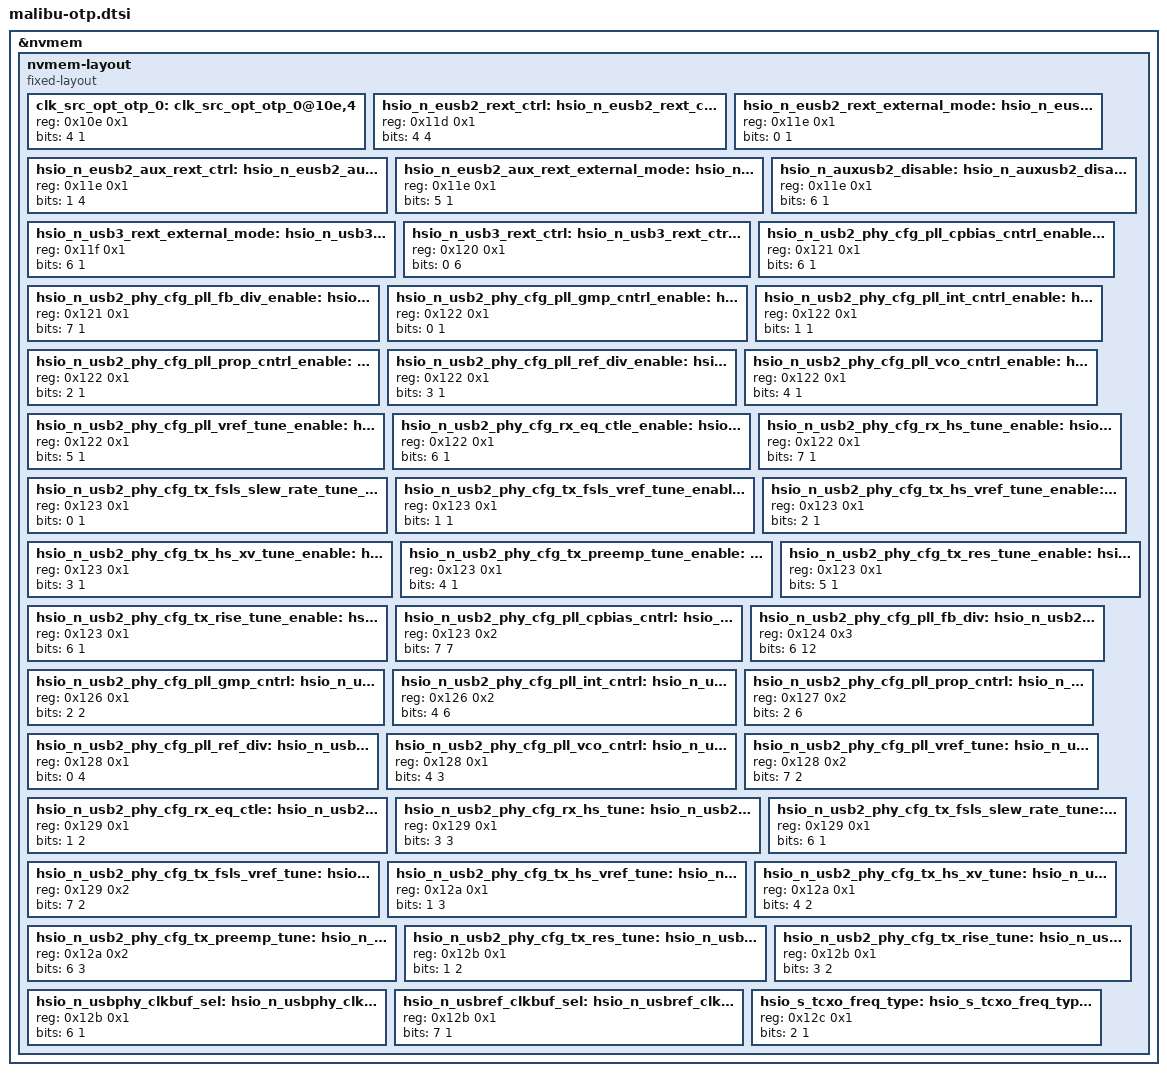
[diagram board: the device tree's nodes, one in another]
// SPDX-License-Identifier: GPL-2.0 OR BSD-3-Clause

&nvmem {
	/* OTPs */
	nvmem-layout {
		compatible = "fixed-layout";
		#address-cells = <1>;
		#size-cells = <1>;

		clk_src_opt_otp_0: clk_src_opt_otp_0@10e,4 {
			reg = <0x10e 0x1>;
			bits = <4 1>;
		};
		hsio_n_eusb2_rext_ctrl: hsio_n_eusb2_rext_ctrl@11d,4 {
			reg = <0x11d 0x1>;
			bits = <4 4>;
		};
		hsio_n_eusb2_rext_external_mode:
			hsio_n_eusb2_rext_external_mode@11e,0 {
			reg = <0x11e 0x1>;
			bits = <0 1>;
		};
		hsio_n_eusb2_aux_rext_ctrl: hsio_n_eusb2_aux_rext_ctrl@11e,1 {
			reg = <0x11e 0x1>;
			bits = <1 4>;
		};
		hsio_n_eusb2_aux_rext_external_mode:
			hsio_n_eusb2_aux_rext_external_mode@11e,5 {
			reg = <0x11e 0x1>;
			bits = <5 1>;
		};
		hsio_n_auxusb2_disable: hsio_n_auxusb2_disable@11e,6 {
			reg = <0x11e 0x1>;
			bits = <6 1>;
		};
		hsio_n_usb3_rext_external_mode:
			hsio_n_usb3_rext_external_mode@11f,6 {
			reg = <0x11f 0x1>;
			bits = <6 1>;
		};
		hsio_n_usb3_rext_ctrl: hsio_n_usb3_rext_ctrl@120,0 {
			reg = <0x120 0x1>;
			bits = <0 6>;
		};
		hsio_n_usb2_phy_cfg_pll_cpbias_cntrl_enable:
			hsio_n_usb2_phy_cfg_pll_cpbias_cntrl_enable@121,6 {
			reg = <0x121 0x1>;
			bits = <6 1>;
		};
		hsio_n_usb2_phy_cfg_pll_fb_div_enable:
			hsio_n_usb2_phy_cfg_pll_fb_div_enable@121,7 {
			reg = <0x121 0x1>;
			bits = <7 1>;
		};
		hsio_n_usb2_phy_cfg_pll_gmp_cntrl_enable:
			hsio_n_usb2_phy_cfg_pll_gmp_cntrl_enable@122,0 {
			reg = <0x122 0x1>;
			bits = <0 1>;
		};
		hsio_n_usb2_phy_cfg_pll_int_cntrl_enable:
			hsio_n_usb2_phy_cfg_pll_int_cntrl_enable@122,1 {
			reg = <0x122 0x1>;
			bits = <1 1>;
		};
		hsio_n_usb2_phy_cfg_pll_prop_cntrl_enable:
			hsio_n_usb2_phy_cfg_pll_prop_cntrl_enable@122,2 {
			reg = <0x122 0x1>;
			bits = <2 1>;
		};
		hsio_n_usb2_phy_cfg_pll_ref_div_enable:
			hsio_n_usb2_phy_cfg_pll_ref_div_enable@122,3 {
			reg = <0x122 0x1>;
			bits = <3 1>;
		};
		hsio_n_usb2_phy_cfg_pll_vco_cntrl_enable:
			hsio_n_usb2_phy_cfg_pll_vco_cntrl_enable@122,4 {
			reg = <0x122 0x1>;
			bits = <4 1>;
		};
		hsio_n_usb2_phy_cfg_pll_vref_tune_enable:
			hsio_n_usb2_phy_cfg_pll_vref_tune_enable@122,5 {
			reg = <0x122 0x1>;
			bits = <5 1>;
		};
		hsio_n_usb2_phy_cfg_rx_eq_ctle_enable:
			hsio_n_usb2_phy_cfg_rx_eq_ctle_enable@122,6 {
			reg = <0x122 0x1>;
			bits = <6 1>;
		};
		hsio_n_usb2_phy_cfg_rx_hs_tune_enable:
			hsio_n_usb2_phy_cfg_rx_hs_tune_enable@122,7 {
			reg = <0x122 0x1>;
			bits = <7 1>;
		};
		hsio_n_usb2_phy_cfg_tx_fsls_slew_rate_tune_enable:
			hsio_n_usb2_phy_cfg_tx_fsls_slew_rate_tune_enable@123,0 {
			reg = <0x123 0x1>;
			bits = <0 1>;
		};
		hsio_n_usb2_phy_cfg_tx_fsls_vref_tune_enable:
			hsio_n_usb2_phy_cfg_tx_fsls_vref_tune_enable@123,1 {
			reg = <0x123 0x1>;
			bits = <1 1>;
		};
		hsio_n_usb2_phy_cfg_tx_hs_vref_tune_enable:
			hsio_n_usb2_phy_cfg_tx_hs_vref_tune_enable@123,2 {
			reg = <0x123 0x1>;
			bits = <2 1>;
		};
		hsio_n_usb2_phy_cfg_tx_hs_xv_tune_enable:
			hsio_n_usb2_phy_cfg_tx_hs_xv_tune_enable@123,3 {
			reg = <0x123 0x1>;
			bits = <3 1>;
		};
		hsio_n_usb2_phy_cfg_tx_preemp_tune_enable:
			hsio_n_usb2_phy_cfg_tx_preemp_tune_enable@123,4 {
			reg = <0x123 0x1>;
			bits = <4 1>;
		};
		hsio_n_usb2_phy_cfg_tx_res_tune_enable:
			hsio_n_usb2_phy_cfg_tx_res_tune_enable@123,5 {
			reg = <0x123 0x1>;
			bits = <5 1>;
		};
		hsio_n_usb2_phy_cfg_tx_rise_tune_enable:
			hsio_n_usb2_phy_cfg_tx_rise_tune_enable@123,6 {
			reg = <0x123 0x1>;
			bits = <6 1>;
		};
		hsio_n_usb2_phy_cfg_pll_cpbias_cntrl:
			hsio_n_usb2_phy_cfg_pll_cpbias_cntrl@123,7 {
			reg = <0x123 0x2>;
			bits = <7 7>;
		};
		hsio_n_usb2_phy_cfg_pll_fb_div:
			hsio_n_usb2_phy_cfg_pll_fb_div@124,6 {
			reg = <0x124 0x3>;
			bits = <6 12>;
		};
		hsio_n_usb2_phy_cfg_pll_gmp_cntrl:
			hsio_n_usb2_phy_cfg_pll_gmp_cntrl@126,2 {
			reg = <0x126 0x1>;
			bits = <2 2>;
		};
		hsio_n_usb2_phy_cfg_pll_int_cntrl:
			hsio_n_usb2_phy_cfg_pll_int_cntrl@126,4 {
			reg = <0x126 0x2>;
			bits = <4 6>;
		};
		hsio_n_usb2_phy_cfg_pll_prop_cntrl:
			hsio_n_usb2_phy_cfg_pll_prop_cntrl@127,2 {
			reg = <0x127 0x2>;
			bits = <2 6>;
		};
		hsio_n_usb2_phy_cfg_pll_ref_div:
			hsio_n_usb2_phy_cfg_pll_ref_div@128,0 {
			reg = <0x128 0x1>;
			bits = <0 4>;
		};
		hsio_n_usb2_phy_cfg_pll_vco_cntrl:
			hsio_n_usb2_phy_cfg_pll_vco_cntrl@128,4 {
			reg = <0x128 0x1>;
			bits = <4 3>;
		};
		hsio_n_usb2_phy_cfg_pll_vref_tune:
			hsio_n_usb2_phy_cfg_pll_vref_tune@128,7 {
			reg = <0x128 0x2>;
			bits = <7 2>;
		};
		hsio_n_usb2_phy_cfg_rx_eq_ctle:
			hsio_n_usb2_phy_cfg_rx_eq_ctle@129,1 {
			reg = <0x129 0x1>;
			bits = <1 2>;
		};
		hsio_n_usb2_phy_cfg_rx_hs_tune:
			hsio_n_usb2_phy_cfg_rx_hs_tune@129,3 {
			reg = <0x129 0x1>;
			bits = <3 3>;
		};
		hsio_n_usb2_phy_cfg_tx_fsls_slew_rate_tune:
			hsio_n_usb2_phy_cfg_tx_fsls_slew_rate_tune@129,6 {
			reg = <0x129 0x1>;
			bits = <6 1>;
		};
		hsio_n_usb2_phy_cfg_tx_fsls_vref_tune:
			hsio_n_usb2_phy_cfg_tx_fsls_vref_tune@129,7 {
			reg = <0x129 0x2>;
			bits = <7 2>;
		};
		hsio_n_usb2_phy_cfg_tx_hs_vref_tune:
			hsio_n_usb2_phy_cfg_tx_hs_vref_tune@12a,1 {
			reg = <0x12a 0x1>;
			bits = <1 3>;
		};
		hsio_n_usb2_phy_cfg_tx_hs_xv_tune:
			hsio_n_usb2_phy_cfg_tx_hs_xv_tune@12a,4 {
			reg = <0x12a 0x1>;
			bits = <4 2>;
		};
		hsio_n_usb2_phy_cfg_tx_preemp_tune:
			hsio_n_usb2_phy_cfg_tx_preemp_tune@12a,6 {
			reg = <0x12a 0x2>;
			bits = <6 3>;
		};
		hsio_n_usb2_phy_cfg_tx_res_tune:
			hsio_n_usb2_phy_cfg_tx_res_tune@12b,1 {
			reg = <0x12b 0x1>;
			bits = <1 2>;
		};
		hsio_n_usb2_phy_cfg_tx_rise_tune:
			hsio_n_usb2_phy_cfg_tx_rise_tune@12b,3 {
			reg = <0x12b 0x1>;
			bits = <3 2>;
		};
		hsio_n_usbphy_clkbuf_sel: hsio_n_usbphy_clkbuf_sel@12b,6 {
			reg = <0x12b 0x1>;
			bits = <6 1>;
		};
		hsio_n_usbref_clkbuf_sel: hsio_n_usbref_clkbuf_sel@12b,7 {
			reg = <0x12b 0x1>;
			bits = <7 1>;
		};
		hsio_s_tcxo_freq_type: hsio_s_tcxo_freq_type@12c,2 {
			reg = <0x12c 0x1>;
			bits = <2 1>;
		};
	};
};
